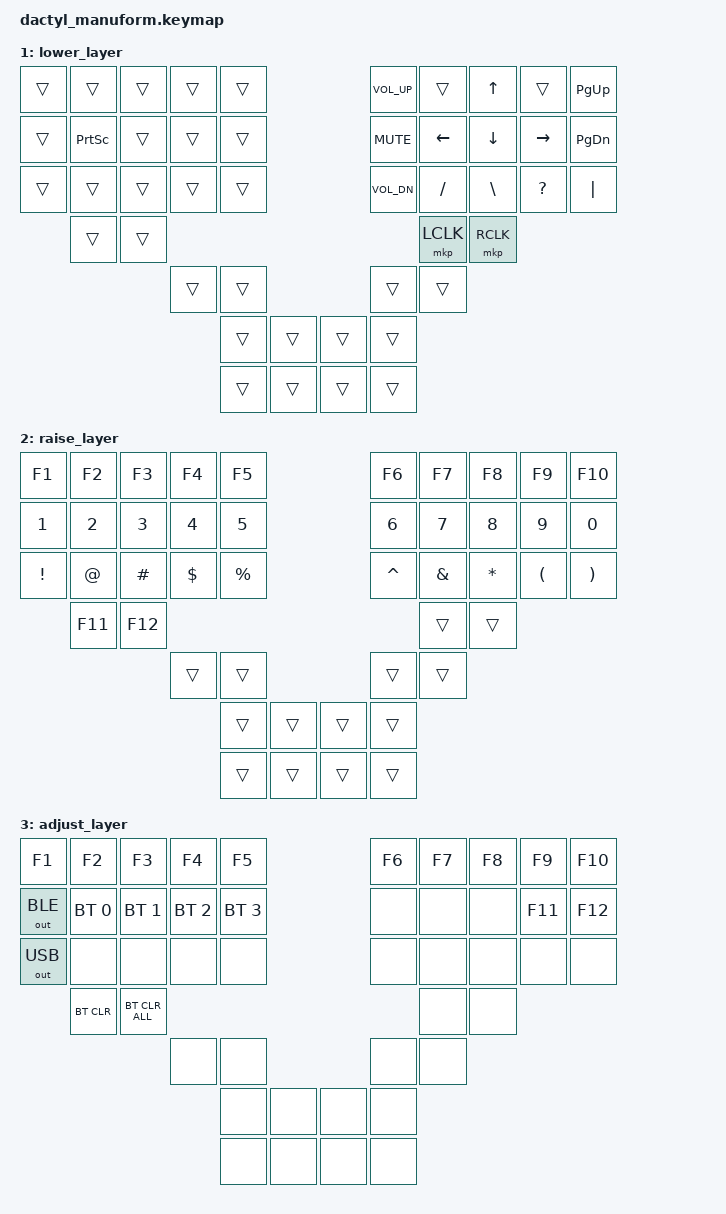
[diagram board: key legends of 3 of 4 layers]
#include <behaviors.dtsi>
#include <dt-bindings/zmk/keys.h>
#include <dt-bindings/zmk/bt.h>
#include <dt-bindings/zmk/outputs.h>
#include <dt-bindings/zmk/mouse.h>

#define DEFAULT 0
#define LOWER 1
#define RAISE 2
#define ADJUST 3

/ {
    keymap {
        compatible = "zmk,keymap";

        default_layer {
            bindings = <
                &kp ESC &kp 1  &kp 2    &kp 3    &kp 4    &kp 5					&kp 6	&kp 7	&kp 8	&kp 9	&kp 0	&kp -
				&kp TAB &kp Q  &kp W    &kp E    &kp R    &kp T                 &kp Y   &kp U   &kp I   &kp O   &kp P &kp \
                &kp LSHIFT  &kp A  &kp S    &kp D    &kp F    &kp G             &kp H   &kp J   &kp K   &kp L   &kp SEMICOLON &mt LSHIFT '
                &kp LCTRL &kp Z  &kp X    &kp C    &kp V    &kp B               &kp N   &kp M   &kp COMMA &kp DOT &kp / &kp RCTRL 
                       &kp LALT &mo LOWER &kp SPACE &kp LWIN                    &kp BSPC &kp ENTER &mo RAISE &kp RALT                                                                                                                  
            >;
        };

        lower_layer {
            bindings = <
                &trans &trans &trans &trans &trans                       &kp C_VOL_UP   &trans       &kp UP    &trans    &kp PG_UP
                &trans &kp PSCRN &trans &trans &trans                       &kp C_MUTE     &kp LEFT     &kp DOWN  &kp RIGHT &kp PG_DN
                &trans &trans &trans &trans &trans                       &kp C_VOL_DN   &kp FSLH     &kp BSLH  &kp QMARK &kp PIPE
                       &trans &trans                                                    &mkp LCLK    &mkp RCLK
                                     &trans &trans                       &trans &trans
                                            &trans &trans         &trans &trans
                                            &trans &trans         &trans &trans
            >;
        };

        raise_layer {
            bindings = <
    &kp F1    &kp F2  &kp F3    &kp F4    &kp F5                        &kp F6     &kp F7    &kp F8      &kp F9    &kp F10
    &kp N1    &kp N2  &kp N3    &kp N4    &kp N5                        &kp N6     &kp N7    &kp N8      &kp N9    &kp N0
    &kp EXCL  &kp AT  &kp HASH  &kp DLLR  &kp PRCNT                     &kp CARET  &kp AMPS  &kp ASTRK   &kp LPAR  &kp RPAR
              &kp F11 &kp F12                                                                &trans      &trans
                                &trans    &trans                        &trans     &trans
                                          &trans    &trans    &trans    &trans
                                          &trans    &trans    &trans    &trans
            >;
        };
	adjust_layer {
            bindings = <
		&kp F1        &kp F2       &kp F3       &kp F4        &kp F5           &kp F6  &kp F7  &kp F8   &kp F9   &kp F10
                &out OUT_BLE  &bt BT_SEL 0 &bt BT_SEL 1 &bt BT_SEL 2  &bt BT_SEL 3     &none   &none   &none    &kp F11  &kp F12
                &out OUT_USB  &none        &none        &none         &none            &none   &none   &none    &none    &none 
                              &bt BT_CLR   &bt BT_CLR_ALL                                              &none    &none
                                                      &none &none                      &none &none
                                                      &none &none                      &none &none
                                                      &none &none                      &none &none
            >;
        };
    };
};
